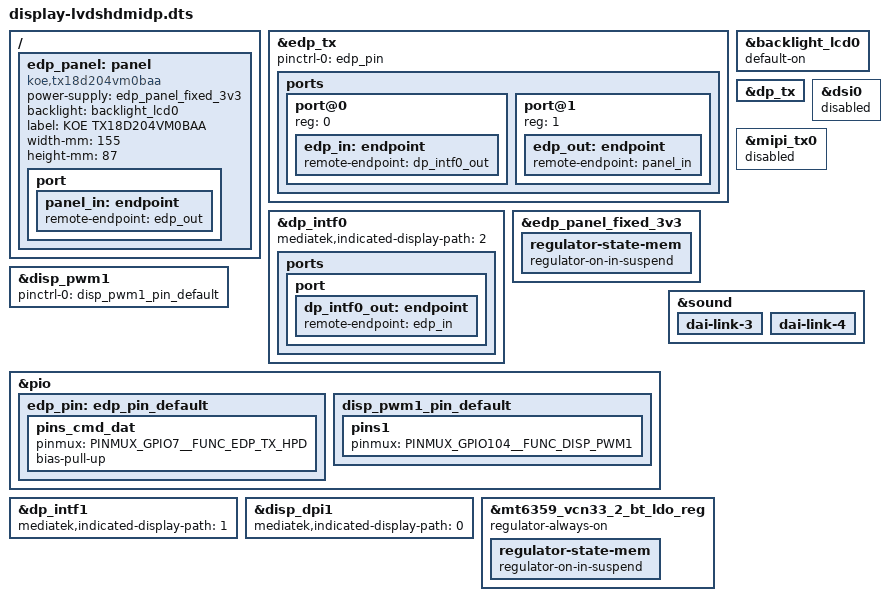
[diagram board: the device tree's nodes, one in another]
/dts-v1/;
/plugin/;

#include <dt-bindings/pinctrl/mt8195-pinfunc.h>

/ {
	fragment@0 {
		target = <&edp_tx>;
		__overlay__ {
			pinctrl-names = "default";
			pinctrl-0 = <&edp_pin>;
			status = "okay";

			ports {
				#address-cells = <1>;
				#size-cells = <0>;

				port@0 {
					reg = <0>;
					edp_in: endpoint {
					remote-endpoint = <&dp_intf0_out>;
					};
				};

				port@1 {
					reg = <1>;
					edp_out: endpoint {
						remote-endpoint = <&panel_in>;
					};
				};
			};
		};
	};

	fragment@1 {
		target = <&dp_intf0>;
		__overlay__ {
			status = "okay";
			mediatek,indicated-display-path = <2>;
			ports {
				port {
					dp_intf0_out: endpoint {
						remote-endpoint = <&edp_in>;
					};
				};
			};
		};
	};

	fragment@2 {
		target-path = "/";
		__overlay__ {
			edp_panel: panel {
				compatible = "koe,tx18d204vm0baa";
				power-supply = <&edp_panel_fixed_3v3>;
				backlight = <&backlight_lcd0>;
				label = "KOE TX18D204VM0BAA";
				width-mm = <155>;
				height-mm = <87>;
				status = "okay";

				port {
					panel_in: endpoint {
						remote-endpoint = <&edp_out>;
					};
				};
			};
		};
	};

	fragment@3 {
		target = <&edp_panel_fixed_3v3>;
		__overlay__ {
			regulator-state-mem {
				regulator-on-in-suspend;
			};
		};
	};

	fragment@4 {
		target = <&backlight_lcd0>;
		__overlay__ {
			default-on;
		};
	};

	fragment@5 {
		target = <&disp_pwm1>;
		__overlay__ {
			status = "okay";
			pinctrl-names = "default";
			pinctrl-0 = <&disp_pwm1_pin_default>;
		};
	};

	fragment@6 {
		target = <&pio>;
		__overlay__ {
			edp_pin: edp_pin_default {
				pins_cmd_dat {
					pinmux = <PINMUX_GPIO7__FUNC_EDP_TX_HPD>;
					bias-pull-up;
				};
			};

			disp_pwm1_pin_default: disp_pwm1_pin_default {
				pins1 {
					pinmux = <PINMUX_GPIO104__FUNC_DISP_PWM1>;
				};
			};
		};
	};

	fragment@7 {
		target = <&dp_tx>;
		__overlay__ {
			status = "okay";
		};
	};

	fragment@8 {
		target = <&dp_intf1>;
		__overlay__ {
			status = "okay";
			mediatek,indicated-display-path = <1>;
		};
	};

	fragment@9 {
		target = <&disp_dpi1>;
		__overlay__ {
			mediatek,indicated-display-path = <0>;
		};
	};

	fragment@10 {
		target = <&dsi0>;
		__overlay__ {
			status = "disabled";
		};
	};

	fragment@11 {
		target = <&mipi_tx0>;
		__overlay__ {
			status = "disabled";
		};
	};

	fragment@12 {
		target = <&sound>;
		__overlay__ {
			dai-link-3 { /* HDMI */
				status = "okay";
			};

			dai-link-4 { /* DPTX */
				status = "okay";
			};
		};
	};

	fragment@13 {
		target = <&mt6359_vcn33_2_bt_ldo_reg>;
		__overlay__ {
			regulator-always-on;
			regulator-state-mem {
				regulator-on-in-suspend;
			};
		};
	};
};
